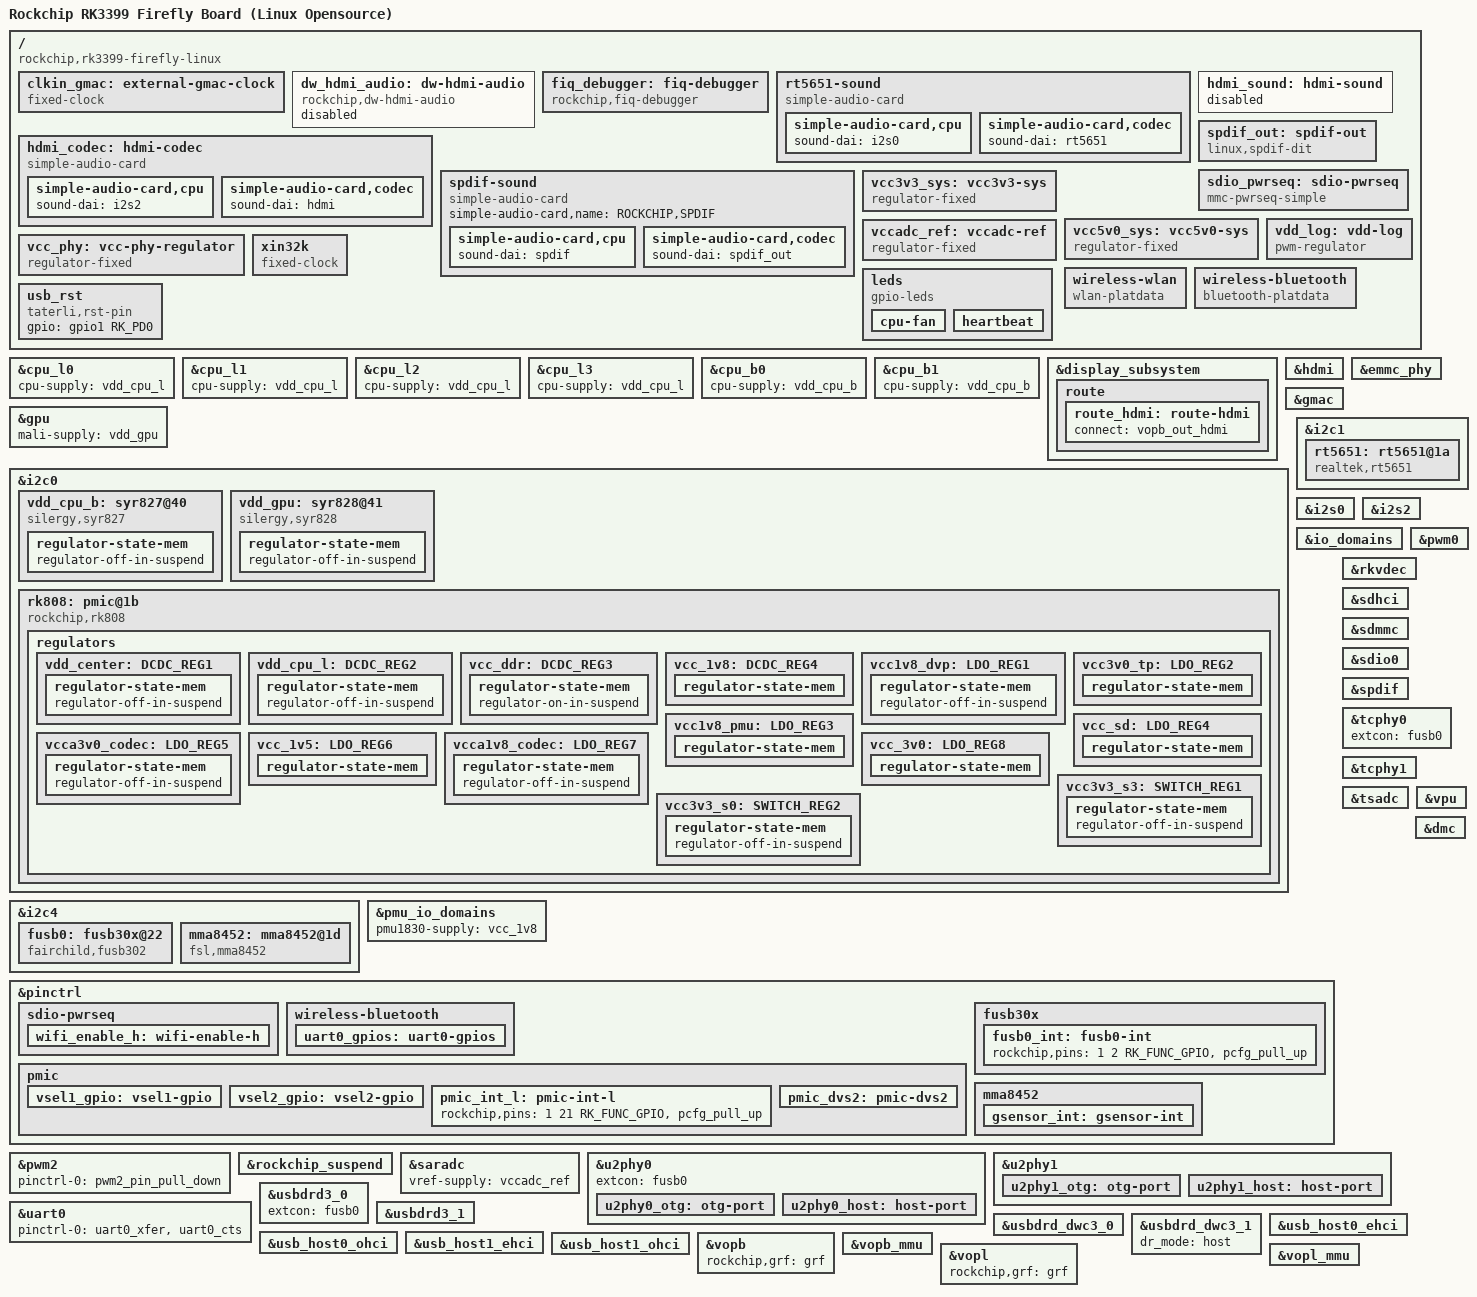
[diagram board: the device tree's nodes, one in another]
/*
 * Copyright (c) 2017 Fuzhou Rockchip Electronics Co., Ltd
 *
 * This file is dual-licensed: you can use it either under the terms
 * of the GPL or the X11 license, at your option. Note that this dual
 * licensing only applies to this file, and not this project as a
 * whole.
 *
 *  a) This file is free software; you can redistribute it and/or
 *     modify it under the terms of the GNU General Public License as
 *     published by the Free Software Foundation; either version 2 of the
 *     License, or (at your option) any later version.
 *
 *     This file is distributed in the hope that it will be useful,
 *     but WITHOUT ANY WARRANTY; without even the implied warranty of
 *     MERCHANTABILITY or FITNESS FOR A PARTICULAR PURPOSE.  See the
 *     GNU General Public License for more details.
 *
 * Or, alternatively,
 *
 *  b) Permission is hereby granted, free of charge, to any person
 *     obtaining a copy of this software and associated documentation
 *     files (the "Software"), to deal in the Software without
 *     restriction, including without limitation the rights to use,
 *     copy, modify, merge, publish, distribute, sublicense, and/or
 *     sell copies of the Software, and to permit persons to whom the
 *     Software is furnished to do so, subject to the following
 *     conditions:
 *
 *     The above copyright notice and this permission notice shall be
 *     included in all copies or substantial portions of the Software.
 *
 *     THE SOFTWARE IS PROVIDED "AS IS", WITHOUT WARRANTY OF ANY KIND,
 *     EXPRESS OR IMPLIED, INCLUDING BUT NOT LIMITED TO THE WARRANTIES
 *     OF MERCHANTABILITY, FITNESS FOR A PARTICULAR PURPOSE AND
 *     NONINFRINGEMENT. IN NO EVENT SHALL THE AUTHORS OR COPYRIGHT
 *     HOLDERS BE LIABLE FOR ANY CLAIM, DAMAGES OR OTHER LIABILITY,
 *     WHETHER IN AN ACTION OF CONTRACT, TORT OR OTHERWISE, ARISING
 *     FROM, OUT OF OR IN CONNECTION WITH THE SOFTWARE OR THE USE OR
 *     OTHER DEALINGS IN THE SOFTWARE.
 */

/dts-v1/;

#include "dt-bindings/pwm/pwm.h"
#include <dt-bindings/soc/rockchip-io-domain.h>
#include "rk3399.dtsi"
#include "rk3399-opp.dtsi"
#include "rk3399-linux.dtsi"
#include <dt-bindings/input/input.h>

/ {
	model = "Rockchip RK3399 Firefly Board (Linux Opensource)";
	compatible = "rockchip,rk3399-firefly-linux", "rockchip,rk3399";

	clkin_gmac: external-gmac-clock {
		compatible = "fixed-clock";
		clock-frequency = <125000000>;
		clock-output-names = "clkin_gmac";
		#clock-cells = <0>;
	};

	dw_hdmi_audio: dw-hdmi-audio {
		status = "disabled";
		compatible = "rockchip,dw-hdmi-audio";
		#sound-dai-cells = <0>;
	};

	fiq_debugger: fiq-debugger {
		compatible = "rockchip,fiq-debugger";
		rockchip,serial-id = <2>;
		rockchip,signal-irq = <182>;
		rockchip,wake-irq = <0>;
		rockchip,irq-mode-enable = <1>;  /* If enable uart uses irq instead of fiq */
		rockchip,baudrate = <1500000>;  /* Only 115200 and 1500000 */
		pinctrl-names = "default";
		pinctrl-0 = <&uart2c_xfer>;
	};
	
	rt5651-sound {
                compatible = "simple-audio-card";
                simple-audio-card,format = "i2s";
                simple-audio-card,name = "realtek,rt5651-codec";
                simple-audio-card,mclk-fs = <256>;
                simple-audio-card,widgets =
                        "Microphone", "Mic Jack",
                        "Headphone", "Headphone Jack";
                simple-audio-card,routing =
                        "Mic Jack", "micbias1",
                        "IN1P", "Mic Jack",
                        "Headphone Jack", "HPOL",
                        "Headphone Jack", "HPOR";
                simple-audio-card,cpu {
                        sound-dai = <&i2s0>;
                };
                simple-audio-card,codec {
                        sound-dai = <&rt5651>;
                };
    };

	hdmi_sound: hdmi-sound {
		status = "disabled";
	};

	hdmi_codec: hdmi-codec {
		compatible = "simple-audio-card";
		simple-audio-card,format = "i2s";
		simple-audio-card,mclk-fs = <256>;
		simple-audio-card,name = "HDMI-CODEC";

		simple-audio-card,cpu {
			sound-dai = <&i2s2>;
		};

		simple-audio-card,codec {
			sound-dai = <&hdmi>;
		};
	};

	spdif-sound {
		status = "okay";
		compatible = "simple-audio-card";
		simple-audio-card,name = "ROCKCHIP,SPDIF";
		simple-audio-card,cpu {
			sound-dai = <&spdif>;
		};
		simple-audio-card,codec {
			sound-dai = <&spdif_out>;
		};
	};

	spdif_out: spdif-out {
		status = "okay";
		compatible = "linux,spdif-dit";
		#sound-dai-cells = <0>;
	};

	sdio_pwrseq: sdio-pwrseq {
		compatible = "mmc-pwrseq-simple";
		clocks = <&rk808 1>;
		clock-names = "ext_clock";
		pinctrl-names = "default";
		pinctrl-0 = <&wifi_enable_h>;

		/*
		 * On the module itself this is one of these (depending
		 * on the actual card populated):
		 * - SDIO_RESET_L_WL_REG_ON
		 * - PDN (power down when low)
		 */
		reset-gpios = <&gpio0 10 GPIO_ACTIVE_LOW>; /* GPIO0_B2 */
	};

	vcc3v3_sys: vcc3v3-sys {
		compatible = "regulator-fixed";
		regulator-name = "vcc3v3_sys";
		regulator-always-on;
		regulator-boot-on;
		regulator-min-microvolt = <3300000>;
		regulator-max-microvolt = <3300000>;
	};

	vcc5v0_sys: vcc5v0-sys {
		compatible = "regulator-fixed";
		regulator-name = "vcc5v0_sys";
		regulator-always-on;
		regulator-boot-on;
		regulator-min-microvolt = <5000000>;
		regulator-max-microvolt = <5000000>;
		gpio = <&gpio4 RK_PD6 GPIO_ACTIVE_HIGH>;
	};

	vcc_phy: vcc-phy-regulator {
		compatible = "regulator-fixed";
		regulator-name = "vcc_phy";
		regulator-always-on;
		regulator-boot-on;
		regulator-min-microvolt = <3300000>;
		regulator-max-microvolt = <3300000>;
	};

	vdd_log: vdd-log {
		compatible = "pwm-regulator";
		pwms = <&pwm2 0 25000 1>;
		regulator-name = "vdd_log";
		/*
		 * the firefly hardware using 3.0 v as APIO2_VDD
		 * voltage, but the pwm divider resistance is designed
		 * based on hardware which the APIO2_VDD is 1.8v.
		 * The correct min-microvolt measure in hardware is 430mV
		 * and the max-microvolt is 1.4V.
		 */
		regulator-min-microvolt = <800000>;
		regulator-max-microvolt = <1400000>;
		regulator-init-microvolt = <1050000>;
		regulator-always-on;
		regulator-boot-on;
		/* 加入电源树 */
		pwm-supply = <&vcc5v0_sys>;
	};

	vccadc_ref: vccadc-ref {
		compatible = "regulator-fixed";
		regulator-name = "vcc1v8_sys";
		regulator-always-on;
		regulator-boot-on;
		regulator-min-microvolt = <1800000>;
		regulator-max-microvolt = <1800000>;
	};

	xin32k: xin32k {
		compatible = "fixed-clock";
		clock-frequency = <32768>;
		clock-output-names = "xin32k";
		#clock-cells = <0>;
	};

	wireless-wlan {
		compatible = "wlan-platdata";
		rockchip,grf = <&grf>;
		wifi_chip_type = "ap6354";
		sdio_vref = <1800>;
		WIFI,host_wake_irq = <&gpio0 3 GPIO_ACTIVE_HIGH>; /* GPIO0_a3 */
		status = "okay";
	};

	wireless-bluetooth {
		compatible = "bluetooth-platdata";
		//wifi-bt-power-toggle;
		uart_rts_gpios = <&gpio2 19 GPIO_ACTIVE_LOW>; /* GPIO2_C3 */
		pinctrl-names = "default", "rts_gpio";
		pinctrl-0 = <&uart0_rts>;
		pinctrl-1 = <&uart0_gpios>;
		//BT,power_gpio  = <&gpio3 19 GPIO_ACTIVE_HIGH>; /* GPIOx_xx */
		BT,reset_gpio    = <&gpio0 9 GPIO_ACTIVE_HIGH>; /* GPIO0_B1 */
		BT,wake_gpio     = <&gpio2 26 GPIO_ACTIVE_HIGH>; /* GPIO2_D2 */
		BT,wake_host_irq = <&gpio0 4 GPIO_ACTIVE_HIGH>; /* GPIO0_A4 */
		status = "okay";
	};

	leds {
		status = "okay";
		compatible = "gpio-leds";
		
		cpu-fan {
			gpios = <&gpio1 RK_PC2 GPIO_ACTIVE_HIGH>;
			linux,default-trigger = "default-on";
			default-state = "on";
		};

		heartbeat {
			gpios = <&gpio4 RK_PD0 GPIO_ACTIVE_LOW>;
			linux,default-trigger = "heartbeat";
			default-state = "on";
		};
	};

	usb_rst {
		status = "okay";
		compatible = "taterli,rst-pin";
		gpio = <&gpio1 RK_PD0 GPIO_ACTIVE_HIGH>;
	};
};


&cpu_l0 {
	cpu-supply = <&vdd_cpu_l>;
};

&cpu_l1 {
	cpu-supply = <&vdd_cpu_l>;
};

&cpu_l2 {
	cpu-supply = <&vdd_cpu_l>;
};

&cpu_l3 {
	cpu-supply = <&vdd_cpu_l>;
};

&cpu_b0 {
	cpu-supply = <&vdd_cpu_b>;
};

&cpu_b1 {
	cpu-supply = <&vdd_cpu_b>;
};

&display_subsystem {
	status = "okay";

	route {
		route_hdmi: route-hdmi {
			status = "okay";
			connect = <&vopb_out_hdmi>;
		};
	};
};


&hdmi {
	#address-cells = <1>;
	#size-cells = <0>;
	#sound-dai-cells = <0>;
	ddc-i2c-scl-high-time-ns = <9625>;
	ddc-i2c-scl-low-time-ns = <10000>;
	status = "okay";
        rockchip,phy-table =
                <74250000  0x8009 0x0004 0x0272>,
                <165000000 0x802b 0x0004 0x0209>,
                <297000000 0x8039 0x0005 0x028d>,
                <594000000 0x8039 0x0000 0x00f6>,
                <000000000 0x0000 0x0000 0x0000>;
};

&emmc_phy {
	status = "okay";
};

&gmac {
	phy-supply = <&vcc_phy>;
	phy-mode = "rgmii";
	clock_in_out = "input";
	snps,reset-gpio = <&gpio3 15 GPIO_ACTIVE_LOW>;
	snps,reset-active-low;
	snps,reset-delays-us = <0 10000 50000>;
	assigned-clocks = <&cru SCLK_RMII_SRC>;
	assigned-clock-parents = <&clkin_gmac>;
	pinctrl-names = "default";
	pinctrl-0 = <&rgmii_pins>;
	tx_delay = <0x28>;
	rx_delay = <0x11>;
	status = "okay";
};

&gpu {
	status = "okay";
	mali-supply = <&vdd_gpu>;
};

&hdmi {
	#address-cells = <1>;
	#size-cells = <0>;
	#sound-dai-cells = <0>;
	status = "okay";
};

&i2c0 {
	status = "okay";
	i2c-scl-rising-time-ns = <168>;
	i2c-scl-falling-time-ns = <4>;
	clock-frequency = <400000>;

	vdd_cpu_b: syr827@40 {
		compatible = "silergy,syr827";
		reg = <0x40>;
		vin-supply = <&vcc5v0_sys>;
		regulator-compatible = "fan53555-reg";
		regulator-name = "vdd_cpu_b";
		pinctrl-names = "default";
        pinctrl-0 = <&vsel1_gpio>;
		regulator-min-microvolt = <712500>;
		regulator-max-microvolt = <1500000>;
		regulator-ramp-delay = <1000>;
		vsel-gpios = <&gpio1 17 GPIO_ACTIVE_HIGH>;
		fcs,suspend-voltage-selector = <1>;
		regulator-always-on;
		regulator-boot-on;
		regulator-initial-state = <3>;
			regulator-state-mem {
			regulator-off-in-suspend;
		};
	};

	vdd_gpu: syr828@41 {
		compatible = "silergy,syr828";
		reg = <0x41>;
		vin-supply = <&vcc5v0_sys>;
		regulator-compatible = "fan53555-reg";
		regulator-name = "vdd_gpu";
		pinctrl-names = "default";
		pinctrl-0 = <&vsel2_gpio>;
		vsel-gpios = <&gpio1 14 GPIO_ACTIVE_HIGH>;
		regulator-min-microvolt = <712500>;
		regulator-max-microvolt = <1500000>;
		regulator-ramp-delay = <1000>;
		fcs,suspend-voltage-selector = <1>;
		regulator-always-on;
		regulator-boot-on;
		regulator-initial-state = <3>;
			regulator-state-mem {
			regulator-off-in-suspend;
		};
	};

	rk808: pmic@1b {
		compatible = "rockchip,rk808";
		reg = <0x1b>;
		interrupt-parent = <&gpio1>;
		interrupts = <21 IRQ_TYPE_LEVEL_LOW>;
		pinctrl-names = "default";
		pinctrl-0 = <&pmic_int_l &pmic_dvs2>;
		rockchip,system-power-controller;
		wakeup-source;
		#clock-cells = <1>;
		clock-output-names = "rk808-clkout1", "rk808-clkout2";

		vcc1-supply = <&vcc5v0_sys>;
		vcc2-supply = <&vcc5v0_sys>;
		vcc3-supply = <&vcc5v0_sys>;
		vcc4-supply = <&vcc5v0_sys>;
		vcca-supply = <&vcc5v0_sys>;
		vcc6-supply = <&vcc5v0_sys>;
		vcc7-supply = <&vcc5v0_sys>;
		vcc8-supply = <&vcc3v3_sys>;
		vcc9-supply = <&vcc5v0_sys>;
		vcc10-supply = <&vcc5v0_sys>;
		vcc11-supply = <&vcc5v0_sys>;
		vcc12-supply = <&vcc3v3_sys>;
		vddio-supply = <&vcc1v8_pmu>;

		regulators {
			vdd_center: DCDC_REG1 {
				regulator-always-on;
				regulator-boot-on;
				regulator-min-microvolt = <750000>;
				regulator-max-microvolt = <1350000>;
				regulator-ramp-delay = <6001>;
				regulator-name = "vdd_center";
				regulator-state-mem {
					regulator-off-in-suspend;
				};
			};

			vdd_cpu_l: DCDC_REG2 {
				regulator-always-on;
				regulator-boot-on;
				regulator-min-microvolt = <750000>;
				regulator-max-microvolt = <1350000>;
				regulator-ramp-delay = <6001>;
				regulator-name = "vdd_cpu_l";
				regulator-state-mem {
					regulator-off-in-suspend;
				};
			};

			vcc_ddr: DCDC_REG3 {
				regulator-always-on;
				regulator-boot-on;
				regulator-name = "vcc_ddr";
				regulator-state-mem {
					regulator-on-in-suspend;
				};
			};

			vcc_1v8: DCDC_REG4 {
				regulator-always-on;
				regulator-boot-on;
				regulator-min-microvolt = <1800000>;
				regulator-max-microvolt = <1800000>;
				regulator-name = "vcc_1v8";
				regulator-state-mem {
					regulator-on-in-suspend;
					regulator-suspend-microvolt = <1800000>;
				};
			};

			vcc1v8_dvp: LDO_REG1 {
				regulator-always-on;
				regulator-boot-on;
				regulator-min-microvolt = <1800000>;
				regulator-max-microvolt = <1800000>;
				regulator-name = "vcc1v8_dvp";
				regulator-state-mem {
					regulator-off-in-suspend;
				};
			};

			vcc3v0_tp: LDO_REG2 {
				regulator-always-on;
				regulator-boot-on;
				regulator-min-microvolt = <3000000>;
				regulator-max-microvolt = <3000000>;
				regulator-name = "vcc3v0_tp";
				regulator-state-mem {
					regulator-on-in-suspend;
					regulator-suspend-microvolt = <3000000>;
				};
			};

			vcc1v8_pmu: LDO_REG3 {
				regulator-always-on;
				regulator-boot-on;
				regulator-min-microvolt = <1800000>;
				regulator-max-microvolt = <1800000>;
				regulator-name = "vcc1v8_pmu";
				regulator-state-mem {
					regulator-on-in-suspend;
					regulator-suspend-microvolt = <1800000>;
				};
			};

			vcc_sd: LDO_REG4 {
				regulator-always-on;
				regulator-boot-on;
				regulator-min-microvolt = <1800000>;
				regulator-max-microvolt = <3000000>;
				regulator-name = "vcc_sd";
				regulator-state-mem {
					regulator-on-in-suspend;
					regulator-suspend-microvolt = <3000000>;
				};
			};

			vcca3v0_codec: LDO_REG5 {
				regulator-always-on;
				regulator-boot-on;
				regulator-min-microvolt = <3000000>;
				regulator-max-microvolt = <3000000>;
				regulator-name = "vcca3v0_codec";
				regulator-state-mem {
					regulator-off-in-suspend;
				};
			};

			vcc_1v5: LDO_REG6 {
				regulator-always-on;
				regulator-boot-on;
				regulator-min-microvolt = <1500000>;
				regulator-max-microvolt = <1500000>;
				regulator-name = "vcc_1v5";
				regulator-state-mem {
					regulator-on-in-suspend;
					regulator-suspend-microvolt = <1500000>;
				};
			};

			vcca1v8_codec: LDO_REG7 {
				regulator-always-on;
				regulator-boot-on;
				regulator-min-microvolt = <1800000>;
				regulator-max-microvolt = <1800000>;
				regulator-name = "vcca1v8_codec";
				regulator-state-mem {
					regulator-off-in-suspend;
				};
			};

			vcc_3v0: LDO_REG8 {
				regulator-always-on;
				regulator-boot-on;
				regulator-min-microvolt = <3000000>;
				regulator-max-microvolt = <3000000>;
				regulator-name = "vcc_3v0";
				regulator-state-mem {
					regulator-on-in-suspend;
					regulator-suspend-microvolt = <3000000>;
				};
			};

			vcc3v3_s3: SWITCH_REG1 {
				regulator-always-on;
				regulator-boot-on;
				regulator-name = "vcc3v3_s3";
				regulator-state-mem {
					regulator-off-in-suspend;
				};
			};

			vcc3v3_s0: SWITCH_REG2 {
				regulator-always-on;
				regulator-boot-on;
				regulator-name = "vcc3v3_s0";
				regulator-state-mem {
					regulator-off-in-suspend;
				};
			};
		};
	};
};

&i2c1 {
	status = "okay";
	i2c-scl-rising-time-ns = <300>;
	i2c-scl-falling-time-ns = <15>;

	rt5651: rt5651@1a {
			#sound-dai-cells = <0>;
			compatible = "realtek,rt5651";
			reg = <0x1a>;
			clocks = <&cru SCLK_I2S_8CH_OUT>;
			clock-names = "mclk";
			pinctrl-names = "default";
			pinctrl-0 = <&i2s_8ch_mclk>;
			spk-con-gpio = <&gpio0 11 GPIO_ACTIVE_HIGH>;
			hp-det-gpio = <&gpio4 28 GPIO_ACTIVE_LOW>;
	};
};

&i2c4 {
	status = "okay";
	i2c-scl-rising-time-ns = <600>;
	i2c-scl-falling-time-ns = <20>;

	fusb0: fusb30x@22 {
		compatible = "fairchild,fusb302";
		reg = <0x22>;
		pinctrl-names = "default";
		pinctrl-0 = <&fusb0_int>;
		int-n-gpios = <&gpio1 2 GPIO_ACTIVE_HIGH>;
		vbus-5v-gpios = <&gpio4 26 GPIO_ACTIVE_HIGH>;
		fusb302,role = "ROLE_MODE_DRP";
		status = "okay";
	};

	mma8452: mma8452@1d {
		compatible = "fsl,mma8452";
		reg = <0x1d>;
		interrupt-parent = <&gpio1>;
		interrupts = <RK_PC7 IRQ_TYPE_EDGE_RISING>;
		pinctrl-names = "default";
		pinctrl-0 = <&gsensor_int>;
	};
};

&i2s0 {
	status = "okay";
	rockchip,i2s-broken-burst-len;
	rockchip,playback-channels = <8>;
	rockchip,capture-channels = <8>;
	#sound-dai-cells = <0>;
};

&i2s2 {
	#sound-dai-cells = <0>;
	status = "okay";
};

&io_domains {
	status = "okay";
	/*
	 * If the uboot use rkdevelop branch, the io-domain is not set
	 * during uboot phase, it will cause the io voltage is not suit for
	 * the hardware,maybe will damage the io of rk3399, so we add
	 * uboot-set value to make sure the value is same with the kernel,
	 * ofcause you must make sure firstly the value here is suit for your
	 * hardware. The available value is defined in
	 * include/dt-bindings/soc/rockchip-io-domain.h, they are
	 * also list here for more convenient configuration:
	 * bt656-supply: RK3399_BT656_VDD_1V8 or RK3399_BT656_VDD_3V3
	 * audio-supply: RK3399_AUDIO_VDD_1V8 or RK3399_AUDIO_VDD_3V3
	 * gpio1830-supply: RK3399_GPIO1833_VDD_1V8 or RK3399_GPIO1833_VDD_3V3
	 * sdmmc-supply: don't need to configure because the voltage
	 *                       is set in source code during runtime.
	 * NOTE:
	 * 1. The value in uboot-set must be enclosed in "()", otherwise will
	 *     cause compile error.
	 * 2. The uboot-set configuration must be cooperated with submit
	 *     in u-boot.
	 */
	bt656-supply = <&vcc_1v8>;		/* bt656_gpio2ab_ms */
	audio-supply = <&vcca1v8_codec>;	/* audio_gpio3d4a_ms */
	sdmmc-supply = <&vcc_sd>;		/* sdmmc_gpio4b_ms */
	gpio1830-supply = <&vcc_3v0>;		/* gpio1833_gpio4cd_ms */
};

&pmu_io_domains {
	status = "okay";
	/*
	 * If the uboot use rkdevelop branch, the pmu_io_domain is not set
	 * during uboot phase, it will cause the io voltage is not suit for
	 * the hardware,maybe will damage the io of rk3399, so we add
	 * uboot-set value to make sure the value is same with the kernel,
	 * ofcause you must make sure firstly the value here is suit for your
	 * hardware. The available value is defined in
	 * include/dt-bindings/soc/rockchip-io-domain.h, they are
	 * also list here for more convenient configuration:
	 * pmu1830-supply: RK3399_PMU1830_VDD_1V8 or RK3399_PMU1830_VDD_3V0
	 */
	pmu1830-supply = <&vcc_1v8>;
};

&pinctrl {
	sdio-pwrseq {
		wifi_enable_h: wifi-enable-h {
			rockchip,pins =
				<0 10 RK_FUNC_GPIO &pcfg_pull_none>;
		};
	};

	wireless-bluetooth {
		uart0_gpios: uart0-gpios {
			rockchip,pins =
				<2 19 RK_FUNC_GPIO &pcfg_pull_none>;
		};
	};

	pmic {
		vsel1_gpio: vsel1-gpio {
			rockchip,pins =
				<1 17 RK_FUNC_GPIO &pcfg_pull_down>;
		};

		vsel2_gpio: vsel2-gpio {
			rockchip,pins =
			<1 14 RK_FUNC_GPIO &pcfg_pull_down>;
		};

		pmic_int_l: pmic-int-l {
			rockchip,pins =
				<1 21 RK_FUNC_GPIO &pcfg_pull_up>;
		};

		pmic_dvs2: pmic-dvs2 {
			rockchip,pins =
				<1 5 RK_FUNC_GPIO &pcfg_pull_down>;
		};
	};

	fusb30x {
		fusb0_int: fusb0-int {
			rockchip,pins = <1 2 RK_FUNC_GPIO &pcfg_pull_up>;
		};
	};

	mma8452 {
		gsensor_int: gsensor-int {
			rockchip,pins = <1 RK_PC7 RK_FUNC_GPIO &pcfg_pull_up>;
		};
	};
};

&pwm0 {
	status = "okay";
};

&pwm2 {
	status = "okay";
	pinctrl-names = "active";
	pinctrl-0 = <&pwm2_pin_pull_down>;
};

&rkvdec {
	status = "okay";
};

&rockchip_suspend {
	status = "okay";
	rockchip,sleep-mode-config = <
		(0
		| RKPM_SLP_ARMPD
		| RKPM_SLP_PERILPPD
		| RKPM_SLP_DDR_RET
		| RKPM_SLP_PLLPD
		| RKPM_SLP_CENTER_PD
		| RKPM_SLP_AP_PWROFF
		)
		>;
	rockchip,wakeup-config = <
		(0
		| RKPM_GPIO_WKUP_EN
		| RKPM_PWM_WKUP_EN
		)
		>;
		rockchip,pwm-regulator-config = <
		(0
		| PWM2_REGULATOR_EN
		)
		>;
	rockchip,power-ctrl =
		<&gpio1 17 GPIO_ACTIVE_HIGH>,
		<&gpio1 14 GPIO_ACTIVE_HIGH>;
};

&saradc {
	status = "okay";
	vref-supply = <&vccadc_ref>;
};

&sdhci {
	bus-width = <8>;
	keep-power-in-suspend;
	mmc-hs400-1_8v;
	mmc-hs400-enhanced-strobe;
	non-removable;
	status = "okay";
	supports-emmc;
};

&sdmmc {
	max-frequency = <150000000>;
	clock-freq-min-max = <100000 150000000>;
	supports-sd;
	bus-width = <4>;
	cap-mmc-highspeed;
	cap-sd-highspeed;
	disable-wp;
	num-slots = <1>;
	vmmc-supply = <&vcc_sd>;
	vqmmc-supply = <&vcc_sd>;
	pinctrl-names = "default";
	pinctrl-0 = <&sdmmc_clk &sdmmc_cmd &sdmmc_cd &sdmmc_bus4>;
	status = "okay";
};

&sdio0 {
	max-frequency = <50000000>;
	clock-freq-min-max = <200000 50000000>;
	supports-sdio;
	bus-width = <4>;
	disable-wp;
	cap-sd-highspeed;
	cap-sdio-irq;
	keep-power-in-suspend;
	mmc-pwrseq = <&sdio_pwrseq>;
	non-removable;
	num-slots = <1>;
	pinctrl-names = "default";
	pinctrl-0 = <&sdio0_bus4 &sdio0_cmd &sdio0_clk>;
	sd-uhs-sdr104;
	status = "okay";
};

&spdif {
	status = "okay";
	pinctrl-0 = <&spdif_bus>;
	i2c-scl-rising-time-ns = <450>;
	i2c-scl-falling-time-ns = <15>;
	#sound-dai-cells = <0>;
};

&tcphy0 {
	extcon = <&fusb0>;
	status = "okay";
};

&tcphy1 {
	status = "okay";
};

&tsadc {
	/* tshut mode 0:CRU 1:GPIO */
	rockchip,hw-tshut-mode = <1>;
	/* tshut polarity 0:LOW 1:HIGH */
	rockchip,hw-tshut-polarity = <1>;
	status = "okay";
};

&u2phy0 {
	status = "okay";
	extcon = <&fusb0>;

	u2phy0_otg: otg-port {
		status = "okay";
	};

	u2phy0_host: host-port {
		status = "okay";
	};
};

&u2phy1 {
	status = "okay";

	u2phy1_otg: otg-port {
		status = "okay";
	};

	u2phy1_host: host-port {
		status = "okay";
	};
};

&uart0 {
	pinctrl-names = "default";
	pinctrl-0 = <&uart0_xfer &uart0_cts>;
	status = "okay";
};

&usbdrd3_0 {
	status = "okay";
	extcon = <&fusb0>;
};

&usbdrd3_1 {
	status = "okay";
};

&usbdrd_dwc3_0 {
	status = "okay";
};

&usbdrd_dwc3_1 {
	status = "okay";
	dr_mode = "host";
};

&usb_host0_ehci {
	status = "okay";
};

&usb_host0_ohci {
	status = "okay";
};

&usb_host1_ehci {
	status = "okay";
};

&usb_host1_ohci {
	status = "okay";
};

&vopb {
	status = "okay";
	rockchip,grf = <&grf>;
};

&vopb_mmu {
	status = "okay";
};

&vopl {
	status = "okay";
	rockchip,grf = <&grf>;
};

&vopl_mmu {
	status = "okay";
};

&vpu {
	status = "okay";
};

&dmc {
	status = "okay";
	center-supply = <&vdd_center>;
	upthreshold = <40>;
	downdifferential = <20>;
	system-status-freq = <
			/*system status         freq(KHz)*/
			SYS_STATUS_NORMAL       800000
			SYS_STATUS_REBOOT       800000
			SYS_STATUS_SUSPEND      800000
			SYS_STATUS_VIDEO_1080P  800000
			SYS_STATUS_VIDEO_4K     800000
			SYS_STATUS_VIDEO_4K_10B 800000
			SYS_STATUS_PERFORMANCE  800000
			SYS_STATUS_BOOST        800000
			SYS_STATUS_DUALVIEW     800000
			SYS_STATUS_ISP          800000
	>;
};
